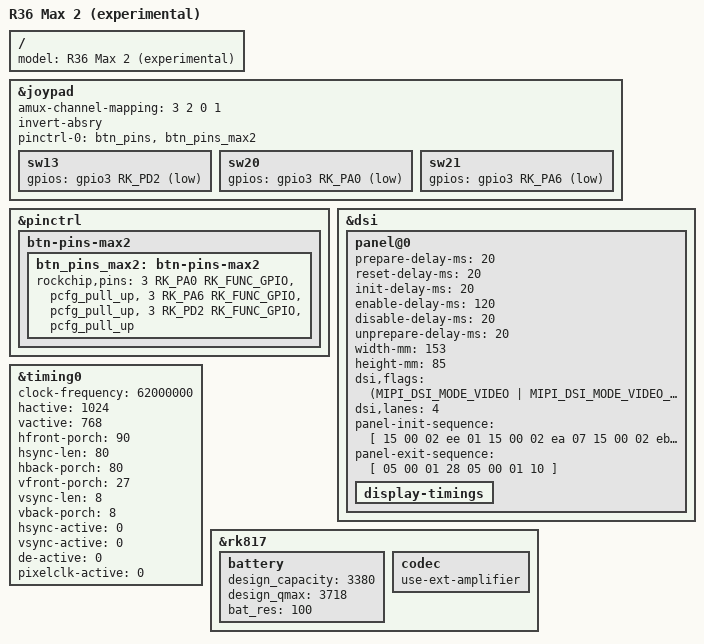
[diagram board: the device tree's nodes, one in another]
// SPDX-License-Identifier: (GPL-2.0+ OR MIT)
/*
 * EXPERIMENTAL - not tested on hardware by andr36oid. Keep a copy of the
 * files you replace so you can go back.
 *
 * R36 Max 2 (arkos4clone "r36max2"; XF45V, RF45H, RF45V and DC45V use the
 * same panel and LCD pins there). G80 wiring: LCD reset GPIO3_D3, LCD power
 * GPIO3_A3. 1024x768 panel with the same init sequence as the R36 Ultra X.
 *
 * Three buttons sit on other pins than on the G80 (stock DTB): R2
 * GPIO3_A0, L2 GPIO3_A6, Fn GPIO3_D2. Sticks: mux order 3 2 0 1.
 * Not carried over (needs hardware): the stock DTB switches USB power on
 * GPIO3_A4 active low (G80: active high) and has a second power switch
 * on GPIO0_A1 for the wifi module.
 * Boot with androidboot.lcd_density=304 as on the R46H.
 *
 * Panel values (delays, size, flags, init and exit sequence, timing) are
 * copied from the reference DTB:
 *   lcdyk0517/arkos4clone @2656e5b6, boot/dArkOS/consoles/r36max2
 *   init sequence 798 bytes, md5 f31ef4f72905
 */

/dts-v1/;

#include "rk3326-r36s-clone-ee.dtsi"

/ {
	model = "R36 Max 2 (experimental)";
};

&joypad {
	amux-channel-mapping = <3 2 0 1>;
	/delete-property/ invert-absy;
	invert-absry;
	pinctrl-0 = <&btn_pins &btn_pins_max2>;

	sw13 {
		gpios = <&gpio3 RK_PD2 GPIO_ACTIVE_LOW>;
	};
	sw20 {
		gpios = <&gpio3 RK_PA0 GPIO_ACTIVE_LOW>;
	};
	sw21 {
		gpios = <&gpio3 RK_PA6 GPIO_ACTIVE_LOW>;
	};
};

&pinctrl {
	btn-pins-max2 {
		btn_pins_max2: btn-pins-max2 {
			rockchip,pins =
				<3 RK_PA0 RK_FUNC_GPIO &pcfg_pull_up>,
				<3 RK_PA6 RK_FUNC_GPIO &pcfg_pull_up>,
				<3 RK_PD2 RK_FUNC_GPIO &pcfg_pull_up>;
		};
	};
};

&dsi {
	panel@0 {
		prepare-delay-ms = <20>;
		reset-delay-ms = <20>;
		init-delay-ms = <20>;
		enable-delay-ms = <120>;
		disable-delay-ms = <20>;
		unprepare-delay-ms = <20>;
		width-mm = <153>;
		height-mm = <85>;
		dsi,flags = <(MIPI_DSI_MODE_VIDEO |
		      MIPI_DSI_MODE_VIDEO_BURST |
		      MIPI_DSI_MODE_EOT_PACKET |
		      MIPI_DSI_MODE_LPM)>;
		dsi,lanes = <4>;
		panel-init-sequence = [
			15 00 02 ee 01
			15 00 02 ea 07
			15 00 02 eb 12
			15 00 02 0a 5e
			15 00 02 13 14
			15 00 02 17 35
			15 00 02 1d 33
			15 00 02 21 01
			15 00 02 28 28
			15 00 02 29 18
			15 00 02 2a 63
			15 00 02 2f f3
			15 00 02 ee 02
			15 00 02 39 a9
			15 00 02 00 00
			15 00 02 01 0d
			15 00 02 02 12
			15 00 02 03 08
			15 00 02 04 0e
			15 00 02 05 30
			15 00 02 06 0b
			15 00 02 07 0e
			15 00 02 08 0f
			15 00 02 09 0e
			15 00 02 0a 11
			15 00 02 0b 4e
			15 00 02 0c 14
			15 00 02 0d 1a
			15 00 02 0e 2f
			15 00 02 0f 36
			15 00 02 10 3f
			15 00 02 20 00
			15 00 02 21 0d
			15 00 02 22 12
			15 00 02 23 08
			15 00 02 24 0e
			15 00 02 25 30
			15 00 02 26 0b
			15 00 02 27 0e
			15 00 02 28 0f
			15 00 02 29 0e
			15 00 02 2a 11
			15 00 02 2b 4e
			15 00 02 2c 14
			15 00 02 2d 1a
			15 00 02 2e 2f
			15 00 02 2f 36
			15 00 02 30 3f
			15 00 02 ee 04
			15 00 02 00 05
			15 00 02 01 01
			15 00 02 02 80
			15 00 02 03 04
			15 00 02 04 00
			15 00 02 06 06
			15 00 02 07 05
			15 00 02 08 1a
			15 00 02 09 20
			15 00 02 0a 0e
			15 00 02 0b 00
			15 00 02 20 40
			15 00 02 24 08
			15 00 02 ee 05
			15 00 02 00 01
			15 00 02 01 09
			15 00 02 02 05
			15 00 02 03 05
			15 00 02 07 05
			15 00 02 08 0d
			15 00 02 09 00
			15 00 02 0a 12
			15 00 02 0b 14
			15 00 02 0c 66
			15 00 02 10 03
			15 00 02 11 07
			15 00 02 12 05
			15 00 02 13 05
			15 00 02 19 12
			15 00 02 1a f6
			15 00 02 40 55
			15 00 02 41 00
			15 00 02 43 03
			15 00 02 44 01
			15 00 02 45 81
			15 00 02 46 06
			15 00 02 47 00
			15 00 02 ee 06
			15 00 02 00 45
			15 00 02 02 01
			15 00 02 04 88
			15 00 02 06 cd
			15 00 02 08 ef
			15 00 02 09 cd
			15 00 02 0a ab
			15 00 02 0b 89
			15 00 02 0c 67
			15 00 02 0d 45
			15 00 02 0e 23
			15 00 02 0f 01
			15 00 02 ee 07
			15 00 02 00 3c
			15 00 02 01 3c
			15 00 02 02 3c
			15 00 02 03 3c
			15 00 02 04 0d
			15 00 02 05 3c
			15 00 02 06 3c
			15 00 02 07 3c
			15 00 02 08 08
			15 00 02 09 10
			15 00 02 0a 12
			15 00 02 0b 14
			15 00 02 0c 16
			15 00 02 0d 18
			15 00 02 0e 1a
			15 00 02 0f 1c
			15 00 02 10 1e
			15 00 02 11 04
			15 00 02 12 00
			15 00 02 13 3c
			15 00 02 14 0c
			15 00 02 15 3c
			15 00 02 20 3c
			15 00 02 21 3c
			15 00 02 22 3c
			15 00 02 23 3c
			15 00 02 24 0d
			15 00 02 25 3c
			15 00 02 26 3c
			15 00 02 27 3c
			15 00 02 28 08
			15 00 02 29 11
			15 00 02 2a 13
			15 00 02 2b 15
			15 00 02 2c 17
			15 00 02 2d 19
			15 00 02 2e 1b
			15 00 02 2f 1d
			15 00 02 30 1f
			15 00 02 31 05
			15 00 02 32 01
			15 00 02 33 3c
			15 00 02 34 0c
			15 00 02 35 3c
			15 00 02 ee 08
			15 00 02 10 00
			15 00 02 12 dc
			15 00 02 13 1c
			15 00 02 17 23
			15 00 02 18 20
			15 00 02 20 80
			15 00 02 ee 0f
			15 00 02 00 01
			15 00 02 01 00
			15 00 02 ee 00
			15 00 02 ea 00
			15 00 02 eb 00
			15 00 02 36 00
			05 c8 01 11
			05 14 01 29
		];
		panel-exit-sequence = [
			05 00 01 28
			05 00 01 10
		];
		display-timings {
			/* one mode only: the R36S alternates do not fit this panel */
			/delete-node/ timing1;
			/delete-node/ timing2;
		};
	};
};

&timing0 {
	clock-frequency = <62000000>;
	hactive = <1024>;
	vactive = <768>;
	hfront-porch = <90>;
	hsync-len = <80>;
	hback-porch = <80>;
	vfront-porch = <27>;	/* was 16: 60.8 Hz; 60.01 Hz, same pixel clock */
	vsync-len = <8>;
	vback-porch = <8>;
	hsync-active = <0>;
	vsync-active = <0>;
	de-active = <0>;
	pixelclk-active = <0>;
};

&rk817 {
	battery {
		/* stock values */
		design_capacity = <3380>;
		design_qmax = <3718>;
		bat_res = <100>;
	};

	/* the speaker runs through an external amplifier (stock "use-ext-amplifier") */
	codec {
		use-ext-amplifier;
	};
};
